# CY8C5868AXI_LP035 register map
File version: 0.1
CY8C58LP
Registers are 8-bit, read-write, no defined reset value unless marked. A register's access mark holds for its fields unless they carry their own. Offsets are from the block's base; lines under a group give offsets from that group; [hi:lo] are bit positions; {n}, {i} and the like mark numbered series; 'fields as' and 'values as' point back to an identical list; <NAME> marks a mode.

## Memory map
0x00000000 XBee — UART
0x00000000 PWM_Front
0x00000000 PWM_Back
0x00000000 Timer_TX
0x00000000 Out_MAX232
0x00000000 Pre_Ampli
0x00000000 Threshold
0x00000000 Chronometer
0x00000000 Counter_Pulses
0x00000000 Comparator
0x40006575 Rotation_Register

## XBee — UART
Base 0x00000000
0x40006528 RX_XBee_RX_ADDRESS1 — RX Address1 Register
0x40006538 RX_XBee_RX_ADDRESS2 — RX Address2 Register
0x40006548 RX_XBee_RX_DATA — RX Data Register
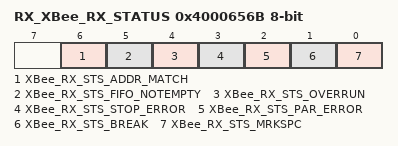
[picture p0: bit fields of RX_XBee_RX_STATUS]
0x4000656B RX_XBee_RX_STATUS — RX status register
  [6] XBee_RX_STS_ADDR_MATCH ro, [5] XBee_RX_STS_FIFO_NOTEMPTY ro, [4] XBee_RX_STS_OVERRUN ro, [3] XBee_RX_STS_STOP_ERROR ro, [2] XBee_RX_STS_PAR_ERROR ro, [1] XBee_RX_STS_BREAK ro, [0] XBee_RX_STS_MRKSPC ro

## Rotation_Register
Base 0x40006575
0x00 Rotation_Register_CONTROL_REG

## PWM_Front
Base 0x00000000
0x40006423 PWM_Front__COMPARE1 — UDB.D0 - Assigned Compare1 Value
0x40006433 PWM_Front__COMPARE2 — UDB.D1 - Assigned Compare2 Value
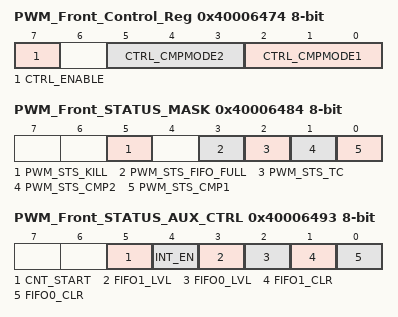
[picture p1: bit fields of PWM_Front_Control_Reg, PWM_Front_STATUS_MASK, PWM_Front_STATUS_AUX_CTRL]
0x40006474 PWM_Front_Control_Reg — UDB Control Register - Assigned Control Register Value
  [7] CTRL_ENABLE — Enable the PWM
  [5:3] CTRL_CMPMODE2 — Compare mode 2
  [2:0] CTRL_CMPMODE1 — Compare mode 1
0x40006484 PWM_Front_STATUS_MASK — UDB Status bits Interrupt Mask Enable Register
  [5] PWM_STS_KILL ro — Enables the Interrupt on Kill
  [3] PWM_STS_FIFO_FULL ro — FIFO Full Status Mask
  [2] PWM_STS_TC ro — Enables the Interrupt on Terminal Count
  [1] PWM_STS_CMP2 ro — Enables the Interrupt on Compare 2
  [0] PWM_STS_CMP1 ro — Enables the Interrupt on Compare 1
0x40006493 PWM_Front_STATUS_AUX_CTRL — UDB Auxilliary Control Register
  [5] CNT_START — FIFO0 clear
    0=E_CNT_START0 (Disable counter); 1=E_CNT_START1 (Enable counter)
  [4] INT_EN
    0=E_INT_EN0 (Interrupt disabled); 1=E_INT_EN1 (Interrupt enabled)
  [3] FIFO1_LVL — FIFO level
    0=E_FIFO_LVL_0 (FIFO LVL: input mode: FIFO not full; output mode: FIFO not empty); 1=E_FIFO_LVL_1 (FIFO LVL: input mode: FIFO at least 1/2 empty; output mode: FIFO at least 1/2 full)
  [2] FIFO0_LVL — FIFO level
    values as FIFO1_LVL
  [1] FIFO1_CLR — FIFO1 clear
    0=E_FIFO_CLR_0 (Normal FIFO operation); 1=E_FIFO_CLR_1 (Clear FIFO state)
  [0] FIFO0_CLR — FIFO0 clear
    values as FIFO1_CLR

## PWM_Back
Base 0x00000000
0x40006422 PWM_Back__COMPARE1 — UDB.D0 - Assigned Compare1 Value
0x40006432 PWM_Back__COMPARE2 — UDB.D1 - Assigned Compare2 Value
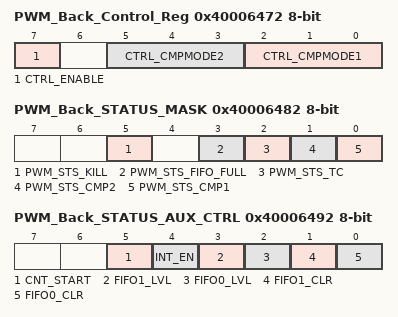
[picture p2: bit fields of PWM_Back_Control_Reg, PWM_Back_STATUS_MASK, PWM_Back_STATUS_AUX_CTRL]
0x40006472 PWM_Back_Control_Reg — UDB Control Register - Assigned Control Register Value
  [7] CTRL_ENABLE — Enable the PWM
  [5:3] CTRL_CMPMODE2 — Compare mode 2
  [2:0] CTRL_CMPMODE1 — Compare mode 1
0x40006482 PWM_Back_STATUS_MASK — UDB Status bits Interrupt Mask Enable Register
  [5] PWM_STS_KILL ro — Enables the Interrupt on Kill
  [3] PWM_STS_FIFO_FULL ro — FIFO Full Status Mask
  [2] PWM_STS_TC ro — Enables the Interrupt on Terminal Count
  [1] PWM_STS_CMP2 ro — Enables the Interrupt on Compare 2
  [0] PWM_STS_CMP1 ro — Enables the Interrupt on Compare 1
0x40006492 PWM_Back_STATUS_AUX_CTRL — UDB Auxilliary Control Register
  [5] CNT_START — FIFO0 clear
    0=E_CNT_START0 (Disable counter); 1=E_CNT_START1 (Enable counter)
  [4] INT_EN
    0=E_INT_EN0 (Interrupt disabled); 1=E_INT_EN1 (Interrupt enabled)
  [3] FIFO1_LVL — FIFO level
    0=E_FIFO_LVL_0 (FIFO LVL: input mode: FIFO not full; output mode: FIFO not empty); 1=E_FIFO_LVL_1 (FIFO LVL: input mode: FIFO at least 1/2 empty; output mode: FIFO at least 1/2 full)
  [2] FIFO0_LVL — FIFO level
    values as FIFO1_LVL
  [1] FIFO1_CLR — FIFO1 clear
    0=E_FIFO_CLR_0 (Normal FIFO operation); 1=E_FIFO_CLR_1 (Clear FIFO state)
  [0] FIFO0_CLR — FIFO0 clear
    values as FIFO1_CLR
